# CY8C5888LTI_LP097 register map
File version: 0.1
Registers are 8-bit, read-write, no defined reset value unless marked. A register's access mark holds for its fields unless they carry their own. Offsets are from the block's base; [hi:lo] are bit positions.

## RegulatorControl
Base 0x00000000
0x40006576 RegulatorControl_CONTROL_REG

## MultiJog_FreqMeter — Count7 debug registers
Base 0x00000000
0x4000647A COUNT 7-bit — Count value register
0x4000648A PERIOD 7-bit — Count7 period register

## FanCtrl
Base 0x00000000
0x400043A3 FanCtrl_GLOBAL_ENABLE — PM.ACT.CFG
  [3:0] en_timer — Enable timer/counters.
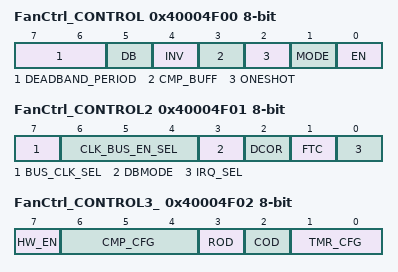
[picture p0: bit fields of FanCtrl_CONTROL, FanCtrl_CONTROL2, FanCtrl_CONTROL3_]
0x40004F00 FanCtrl_CONTROL — TMRx.CFG0
  [7:6] DEADBAND_PERIOD
  [5] DB — Deadband mode--Deadband phases phi1 and phi2 are outputted on CMP and TC output pins respectively.
    0=Timer (CMP and TC are output.); 1=Deadband (PHI1 (instead of CMP) and PHI2 (instead of TC) are output.)
  [4] INV — Invert sense of TIMEREN signal
  [3] CMP_BUFF — Buffer compare register. Compare register updates only on timer terminal count.
  [2] ONESHOT — Timer stops upon reaching stop condition defined by TMR_CFG bits. Can be restarted by asserting TIMER RESET or disabling and re-enabling block.
  [1] MODE — Mode. (0 = Timer; 1 = Comparator)
    0=Timer mode. CNT/CMP register holds timer count value.; 1=Comparator mode. CNT/CMP register holds comparator threshold value.
  [0] EN — Enables timer/comparator.
0x40004F01 FanCtrl_CONTROL2 — TMRx.CFG1
  [7] BUS_CLK_SEL — Bus Clock selection.
  [6:4] CLK_BUS_EN_SEL — Digital Global Clock selection.
  [3] DBMODE — Deadband mode (asynchronous/synchronous). CMP output pin is also affected when not in deadband mode (CFG0.DEADBAND).
  [2] DCOR — Disable Clear on Read (DCOR) of Status Register SR0.
  [1] FTC — First Terminal Count (FTC). Setting this bit forces a single pulse on the TC pin when first enabled.
    0=Disable_FTC (Disable the single cycle pulse, which signifies the timer is starting.); 1=Enable_FTC (Enable the single cycle pulse, which signifies the timer is starting.)
  [0] IRQ_SEL — Irq selection. (0 = raw interrupts; 1 = status register interrupts)
0x40004F02 FanCtrl_CONTROL3_ — TMRx.CFG2
  [7] HW_EN — When set Timer Enable controls counting.
  [6:4] CMP_CFG — Comparator configurations
    0=Equal (Compare Equal); 1=Less_than (Compare Less Than); 2=Less_than_or_equal (Compare Less Than or Equal .); 3=Greater (Compare Greater Than .); 4=Greater_than_or_equal (Compare Greater Than or Equal)
  [3] ROD — Reset On Disable (ROD). Resets internal state of output logic
  [2] COD — Clear On Disable (COD). Clears or gates outputs to zero.
  [1:0] TMR_CFG — Timer configuration (MODE = 0): 000 = Continuous; 001 = Pulsewidth; 010 = Period; 011 = Stop on IRQ
    0=Continuous (Timer runs while EN bit of CFG0 register is set to '1'.); 1=Pulsewidth (Timer runs from positive to negative edge of TIMEREN.); 2=Period (Timer runs from positive to positive edge of TIMEREN.); 3=Irq (Timer runs until IRQ.)
0x40004F04 FanCtrl_PERIOD — TMRx.PER0 - Assigned Period
0x40004F06 FanCtrl_COMPARE — TMRx.CNT_CMP0 - Assigned Compare Value

## Count7_OverAmperageA — Count7 debug registers
Base 0x00000000
0x40006476 COUNT 7-bit — Count value register
0x40006486 PERIOD 7-bit — Count7 period register

## Count7_OverVoltageA — Count7 debug registers
Base 0x00000000
0x40006475 COUNT 7-bit — Count value register
0x40006485 PERIOD 7-bit — Count7 period register

## Count7_VoltageA_Ex — Count7 debug registers
Base 0x00000000
0x4000657B COUNT 7-bit — Count value register
0x4000658B PERIOD 7-bit — Count7 period register

## Count7_OverVoltageB — Count7 debug registers
Base 0x00000000
0x40006574 COUNT 7-bit — Count value register
0x40006584 PERIOD 7-bit — Count7 period register

## Count7_OverAmperageB — Count7 debug registers
Base 0x00000000
0x40006575 COUNT 7-bit — Count value register
0x40006585 PERIOD 7-bit — Count7 period register
